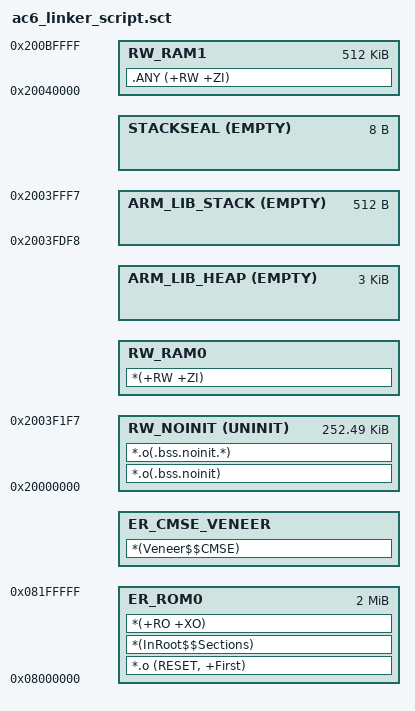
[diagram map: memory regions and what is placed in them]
# 1 "D:/GitHub/DavidLesnjak/STM32CubeMX_Gaps-projects/secure_nonsecure/prj_secure/RTE/Device/STM32U585AIIx/ac6_linker_script.sct.src"
# 1 "<built-in>" 1
# 1 "<built-in>" 3
# 404 "<built-in>" 3
# 1 "<command line>" 1
# 1 "<built-in>" 2
# 1 "D:/GitHub/DavidLesnjak/STM32CubeMX_Gaps-projects/secure_nonsecure/prj_secure/RTE/Device/STM32U585AIIx/regions_B_U585I_IOT02A.h" 1
# 2 "<built-in>" 2
# 1 "D:/GitHub/DavidLesnjak/STM32CubeMX_Gaps-projects/secure_nonsecure/prj_secure/RTE/Device/STM32U585AIIx/ac6_linker_script.sct.src" 2
# 32 "D:/GitHub/DavidLesnjak/STM32CubeMX_Gaps-projects/secure_nonsecure/prj_secure/RTE/Device/STM32U585AIIx/ac6_linker_script.sct.src"
LR_ROM0 0x08000000 0x00200000 {

  ER_ROM0 0x08000000 0x00200000 {
    *.o (RESET, +First)
    *(InRoot$$Sections)
    *(+RO +XO)
  }


  ER_CMSE_VENEER AlignExpr(+0, 32) (0x00200000 - AlignExpr(ImageLength(ER_ROM0), 32)) {
    *(Veneer$$CMSE)
  }


  RW_NOINIT 0x20000000 UNINIT (0x00040000 - 0x00000C00 - 0x00000200 - 8) {
    *.o(.bss.noinit)
    *.o(.bss.noinit.*)
  }

  RW_RAM0 AlignExpr(+0, 8) (0x00040000 - 0x00000C00 - 0x00000200 - 8 - AlignExpr(ImageLength(RW_NOINIT), 8)) {
    *(+RW +ZI)
  }


  ARM_LIB_HEAP (AlignExpr(+0, 8)) EMPTY 0x00000C00 { ; Reserve empty region for heap
  }


  ARM_LIB_STACK (0x20000000 + 0x00040000 - 8) EMPTY -0x00000200 { ; Reserve empty region for stack
  }


  STACKSEAL +0 EMPTY 8 { ; Reserve empty region for stack seal immediately after stack
  }



  RW_RAM1 0x20040000 0x00080000 {
   .ANY (+RW +ZI)
  }
# 85 "D:/GitHub/DavidLesnjak/STM32CubeMX_Gaps-projects/secure_nonsecure/prj_secure/RTE/Device/STM32U585AIIx/ac6_linker_script.sct.src"
}
